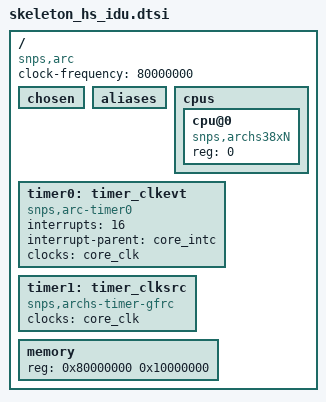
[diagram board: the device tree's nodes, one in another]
/*
 * Copyright (C) 2016 Synopsys, Inc. (www.synopsys.com)
 *
 * This program is free software; you can redistribute it and/or modify
 * it under the terms of the GNU General Public License version 2 as
 * published by the Free Software Foundation.
 */

/ {
	compatible = "snps,arc";
	clock-frequency = <80000000>;	/* 80 MHZ */
	#address-cells = <1>;
	#size-cells = <1>;
	chosen { };
	aliases { };

	cpus {
		#address-cells = <1>;
		#size-cells = <0>;

		cpu@0 {
			device_type = "cpu";
			compatible = "snps,archs38xN";
			reg = <0>;
		};
	};

	timer0: timer_clkevt {
		compatible = "snps,arc-timer0";
		interrupts = <16>;
		interrupt-parent = <&core_intc>;
		clocks = <&core_clk>;
	};

	timer1: timer_clksrc {
		compatible = "snps,archs-timer-gfrc";
		clocks = <&core_clk>;
	};

	memory {
		device_type = "memory";
		reg = <0x80000000 0x10000000>;	/* 256M */
	};
};
